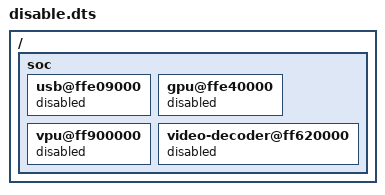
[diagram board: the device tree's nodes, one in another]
/ {
    soc {
        usb@ffe09000 {
            status = "disabled";
        };

        gpu@ffe40000 {
            status = "disabled";
        };

        vpu@ff900000 {
            status = "disabled";
        };

        video-decoder@ff620000 {
            status = "disabled";
        };
    };
};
